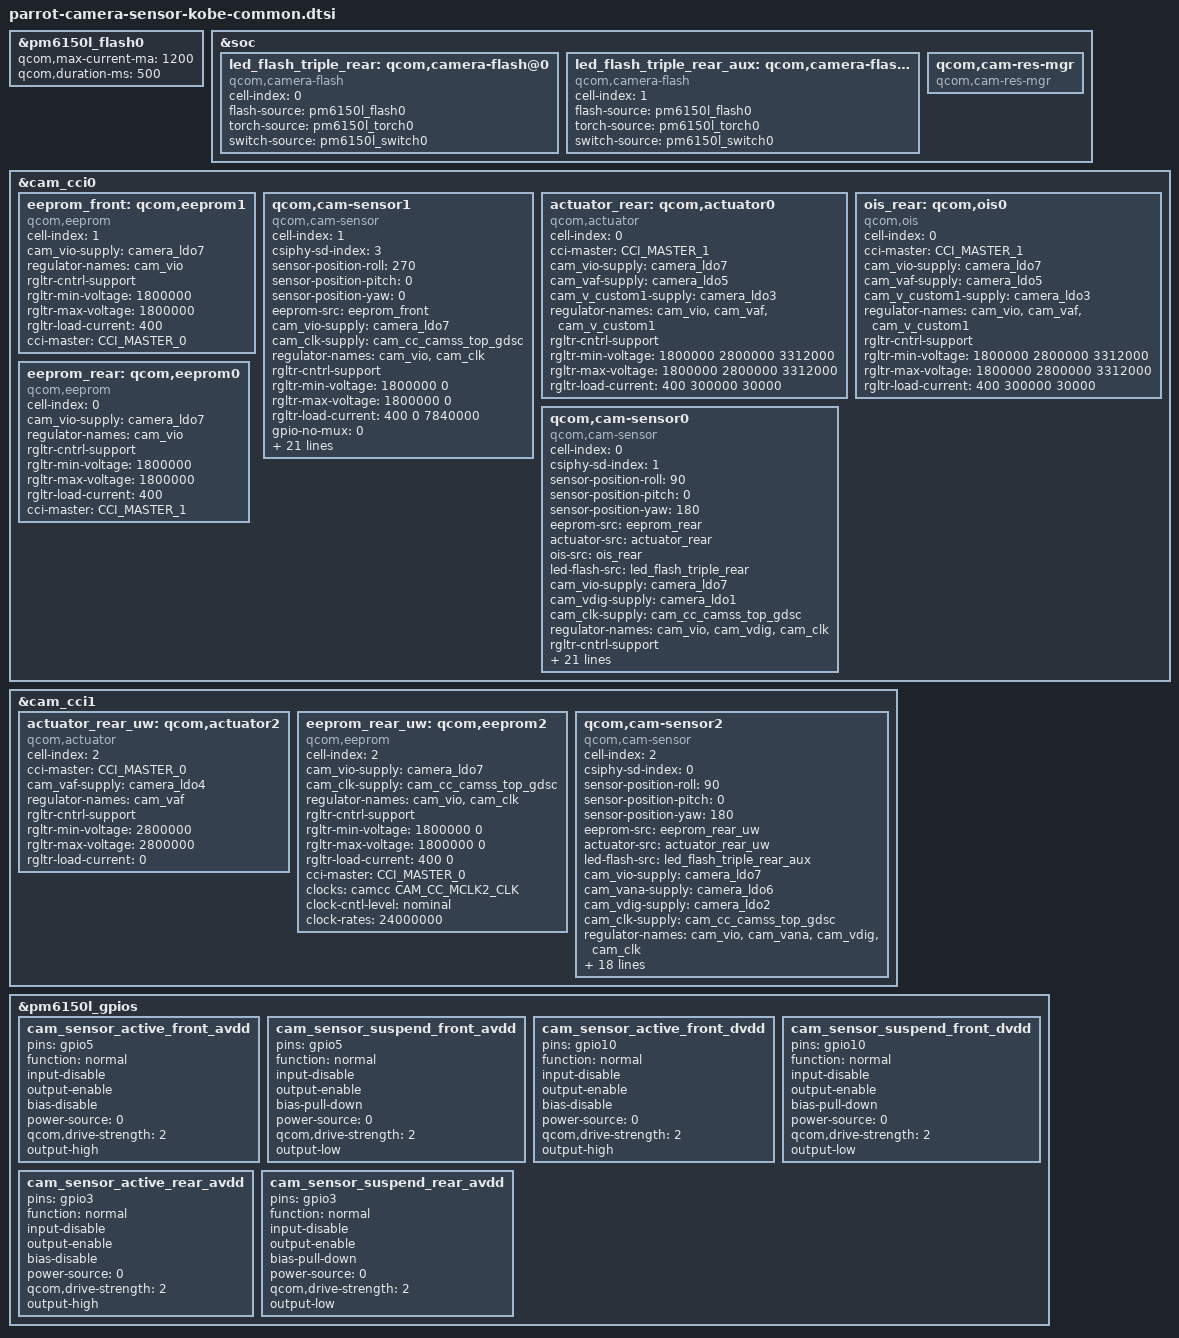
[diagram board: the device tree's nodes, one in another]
#include <dt-bindings/clock/qcom,camcc-parrot.h>
#include <dt-bindings/msm-camera.h>

&pm6150l_flash0{
	qcom,max-current-ma = <1200>;
	qcom,duration-ms = <500>;
};

&soc {
	led_flash_triple_rear: qcom,camera-flash@0 {
		cell-index = <0>;
		compatible = "qcom,camera-flash";
		flash-source = <&pm6150l_flash0>;
		torch-source = <&pm6150l_torch0>;
		switch-source = <&pm6150l_switch0>;
		status = "ok";
	};

	led_flash_triple_rear_aux: qcom,camera-flash@1 {
		cell-index = <1>;
		compatible = "qcom,camera-flash";
		flash-source = <&pm6150l_flash0>;
		torch-source = <&pm6150l_torch0>;
		switch-source = <&pm6150l_switch0>;
		status = "ok";
	};

	qcom,cam-res-mgr {
		compatible = "qcom,cam-res-mgr";
		status = "ok";
	};
};

&cam_cci0 {
	eeprom_front: qcom,eeprom1 {
		cell-index = <1>;
		compatible = "qcom,eeprom";
		cam_vio-supply = <&camera_ldo7>;
		regulator-names = "cam_vio";
		rgltr-cntrl-support;
		rgltr-min-voltage = <1800000>;
		rgltr-max-voltage = <1800000>;
		rgltr-load-current = <400>; // power dependent
		cci-master = <CCI_MASTER_0>;
		status = "ok";
	};

	qcom,cam-sensor1 {
		cell-index = <1>;
		compatible = "qcom,cam-sensor";
		csiphy-sd-index = <3>;
		sensor-position-roll = <270>;
		sensor-position-pitch = <0>;
		sensor-position-yaw = <0>;
		eeprom-src = <&eeprom_front>;
		cam_vio-supply = <&camera_ldo7>;
		cam_clk-supply = <&cam_cc_camss_top_gdsc>;
		regulator-names = "cam_vio", "cam_clk";
		rgltr-cntrl-support;
		rgltr-min-voltage = <1800000 0>;
		rgltr-max-voltage = <1800000 0>;
		rgltr-load-current = <400 0 7840000>; // power dependent
		gpio-no-mux = <0>;
		pinctrl-names = "cam_default", "cam_suspend";
		pinctrl-0 = <&cam_sensor_mclk0_active
				 &cam_sensor_active_rst0
				 &cam_sensor_active_front_avdd
				 &cam_sensor_active_front_dvdd>;
		pinctrl-1 = <&cam_sensor_mclk0_suspend
				 &cam_sensor_suspend_rst0
				 &cam_sensor_suspend_front_avdd
				 &cam_sensor_suspend_front_dvdd>;
		gpios = <&tlmm 39 0>,
			<&tlmm 44 0>,
			<&pm6150l_gpios 5 0>, // AVDD 2.8V
			<&pm6150l_gpios 10 0>; // DVDD 1.1V
		gpio-reset = <1>;
		gpio-vana = <2>;
		gpio-vdig = <3>;
		gpio-req-tbl-num = <0 1 2 3>;
		gpio-req-tbl-flags = <1 0 0 0>;
		gpio-req-tbl-label = "CAMIF_MCLK0",
					"CAM_RESET0", "CAM_FRONT_AVDD_2P8", "CAM_FRONT_DVDD_1P2";
		cci-master = <CCI_MASTER_0>;
		clocks = <&camcc CAM_CC_MCLK0_CLK>;
		clock-names = "cam_clk";
		clock-cntl-level = "nominal";
		clock-rates = <24000000>;
		status = "ok";
	};

	actuator_rear: qcom,actuator0 {
		cell-index = <0>;
		compatible = "qcom,actuator";
		cci-master = <CCI_MASTER_1>;
		cam_vio-supply = <&camera_ldo7>;
		cam_vaf-supply = <&camera_ldo5>;
		cam_v_custom1-supply = <&camera_ldo3>; // OISVDD
		regulator-names = "cam_vio", "cam_vaf", "cam_v_custom1";
		rgltr-cntrl-support;
		rgltr-min-voltage = <1800000 2800000 3312000>;
		rgltr-max-voltage = <1800000 2800000 3312000>;
		rgltr-load-current = <400 300000 30000>;
		status = "ok";
	};

	ois_rear: qcom,ois0 {
		cell-index = <0>;
		compatible = "qcom,ois";
		cci-master = <CCI_MASTER_1>;
		cam_vio-supply = <&camera_ldo7>;
		cam_vaf-supply = <&camera_ldo5>;
		cam_v_custom1-supply = <&camera_ldo3>; // OISVDD
		regulator-names = "cam_vio", "cam_vaf", "cam_v_custom1";
		rgltr-cntrl-support;
		rgltr-min-voltage = <1800000 2800000 3312000>;
		rgltr-max-voltage = <1800000 2800000 3312000>;
		rgltr-load-current = <400 300000 30000>;
		status = "ok";
	};

	eeprom_rear: qcom,eeprom0 {
		cell-index = <0>;
		compatible = "qcom,eeprom";
		cam_vio-supply = <&camera_ldo7>;
		regulator-names = "cam_vio";
		rgltr-cntrl-support;
		rgltr-min-voltage = <1800000>;
		rgltr-max-voltage = <1800000>;
		rgltr-load-current = <400>; // power dependent
		cci-master = <CCI_MASTER_1>;
		status = "ok";
	};

	qcom,cam-sensor0 {
		cell-index = <0>;
		compatible = "qcom,cam-sensor";
		csiphy-sd-index = <1>;
		sensor-position-roll = <90>;
		sensor-position-pitch = <0>;
		sensor-position-yaw = <180>;
		eeprom-src = <&eeprom_rear>;
		actuator-src = <&actuator_rear>;
		ois-src = <&ois_rear>;
		led-flash-src = <&led_flash_triple_rear>;
		cam_vio-supply = <&camera_ldo7>;
		cam_vdig-supply = <&camera_ldo1>;
		cam_clk-supply = <&cam_cc_camss_top_gdsc>;
		regulator-names = "cam_vio", "cam_vdig", "cam_clk";
		rgltr-cntrl-support;
		rgltr-min-voltage = <1800000 1104000 0>;
		rgltr-max-voltage = <1800000 1104000 0>;
		rgltr-load-current = <0 0 0>; // power dependent
		gpio-no-mux = <0>;
		pinctrl-names = "cam_default", "cam_suspend";
		pinctrl-0 = <&cam_sensor_mclk1_active
				 &cam_sensor_active_rst1
				 &cam_sensor_active_rear_avdd>;
		pinctrl-1 = <&cam_sensor_mclk1_suspend
				 &cam_sensor_suspend_rst1
				 &cam_sensor_suspend_rear_avdd>;
		gpios = <&tlmm 40 0>,
			<&tlmm 45 0>,
			<&pm6150l_gpios 3 0>;
		gpio-reset = <1>;
		gpio-standby = <2>; // AVDD
		gpio-req-tbl-num = <0 1 2>;
		gpio-req-tbl-flags = <1 0 0>;
		gpio-req-tbl-label = "CAMIF_MCLK1",
					"CAM_RESET1", "CAM_REAR_AVDD";
		cci-master = <CCI_MASTER_1>;
		clocks = <&camcc CAM_CC_MCLK1_CLK>;
		clock-names = "cam_clk";
		clock-cntl-level = "nominal";
		clock-rates = <24000000>;
		status = "ok";
	};
};

&cam_cci1 {
	actuator_rear_uw: qcom,actuator2 {
		cell-index = <2>;
		compatible = "qcom,actuator";
		cci-master = <CCI_MASTER_0>;
		cam_vaf-supply = <&camera_ldo4>;
		regulator-names = "cam_vaf";
		rgltr-cntrl-support;
		rgltr-min-voltage = <2800000>;
		rgltr-max-voltage = <2800000>;
		rgltr-load-current = <0>;
	};

	eeprom_rear_uw: qcom,eeprom2 {
		cell-index = <2>;
		compatible = "qcom,eeprom";
		cam_vio-supply = <&camera_ldo7>;
		cam_clk-supply = <&cam_cc_camss_top_gdsc>;
		regulator-names = "cam_vio", "cam_clk";
		rgltr-cntrl-support;
		rgltr-min-voltage = <1800000 0>;
		rgltr-max-voltage = <1800000 0>;
		rgltr-load-current = <400 0>;
		cci-master = <CCI_MASTER_0>;
		clocks = <&camcc CAM_CC_MCLK2_CLK>;
		clock-names = "cam_clk";
		clock-cntl-level = "nominal";
		clock-rates = <24000000>;
		status = "ok";
	};

	qcom,cam-sensor2 {
		cell-index = <2>;
		compatible = "qcom,cam-sensor";
		csiphy-sd-index = <0>;
		sensor-position-roll = <90>;
		sensor-position-pitch = <0>;
		sensor-position-yaw = <180>;
		eeprom-src = <&eeprom_rear_uw>;
		actuator-src = <&actuator_rear_uw>;
		led-flash-src = <&led_flash_triple_rear_aux>;
		cam_vio-supply = <&camera_ldo7>;
		cam_vana-supply = <&camera_ldo6>;
		cam_vdig-supply = <&camera_ldo2>;
		cam_clk-supply = <&cam_cc_camss_top_gdsc>;
		regulator-names = "cam_vio", "cam_vana","cam_vdig", "cam_clk";
		rgltr-cntrl-support;
		rgltr-min-voltage = <1800000 2800000 1200000 0>;
		rgltr-max-voltage = <1800000 2800000 1200000 0>;
		rgltr-load-current = <0 0 0 0>;
		gpio-no-mux = <0>;
		pinctrl-names = "cam_default", "cam_suspend";
		pinctrl-0 = <&cam_sensor_mclk2_active
				&cam_sensor_active_rst2>;
		pinctrl-1 = <&cam_sensor_mclk2_suspend
				&cam_sensor_suspend_rst2>;
		gpios = <&tlmm 41 0>,
			<&tlmm 46 0>;
		gpio-reset = <1>;
		gpio-req-tbl-num = <0 1>;
		gpio-req-tbl-flags = <1 0>;
		gpio-req-tbl-label = "CAMIF_MCLK2",
					"CAM_RESET2";
		cci-master = <CCI_MASTER_0>;
		clocks = <&camcc CAM_CC_MCLK2_CLK>;
		clock-names = "cam_clk";
		clock-cntl-level = "nominal";
		clock-rates = <24000000>;
		status = "ok";
	};
};

&pm6150l_gpios {
	cam_sensor_active_front_avdd: cam_sensor_active_front_avdd {
		/* CAMERA FRONT AVDD, ACTIVATE WL2848D28 */
		pins = "gpio5";
		function = "normal";
		input-disable;
		output-enable;
		bias-disable;
		power-source = <0>;
		qcom,drive-strength = <2>;
		output-high;
	};

	cam_sensor_suspend_front_avdd: cam_sensor_suspend_front_avdd {
		/* CAMERA FRONT AVDD, DEACTIVATE WL2848D28 */
		pins = "gpio5";
		function = "normal";
		input-disable;
		output-enable;
		bias-pull-down;
		power-source = <0>;
		qcom,drive-strength = <2>;
		output-low;
	};

	cam_sensor_active_front_dvdd: cam_sensor_active_front_dvdd {
		/* CAMERA FRONT DVDD, ACTIVATE WL2831D11 */
		pins = "gpio10";
		function = "normal";
		input-disable;
		output-enable;
		bias-disable;
		power-source = <0>;
		qcom,drive-strength = <2>;
		output-high;
	};

	cam_sensor_suspend_front_dvdd: cam_sensor_suspend_front_dvdd {
		/* CAMERA FRONT DVDD, DEACTIVATE WL2831D11 */
		pins = "gpio10";
		function = "normal";
		input-disable;
		output-enable;
		bias-pull-down;
		power-source = <0>;
		qcom,drive-strength = <2>;
		output-low;
	};

	cam_sensor_active_rear_avdd: cam_sensor_active_rear_avdd {
		/* CAMERA REAR AVDD, ACTIVATE WL2848D28 */
		pins = "gpio3";
		function = "normal";
		input-disable;
		output-enable;
		bias-disable;
		power-source = <0>;
		qcom,drive-strength = <2>;
		output-high;
	};

	cam_sensor_suspend_rear_avdd: cam_sensor_suspend_rear_avdd {
		/* CAMERA REAR AVDD, DEACTIVATE WL2848D28 */
		pins = "gpio3";
		function = "normal";
		input-disable;
		output-enable;
		bias-pull-down;
		power-source = <0>;
		qcom,drive-strength = <2>;
		output-low;
	};
};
